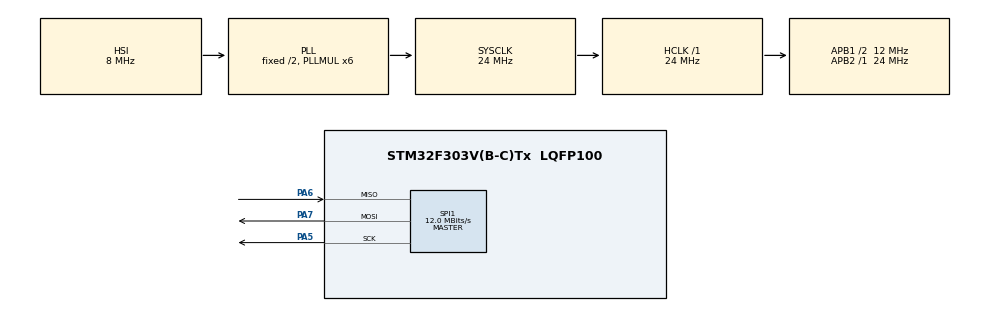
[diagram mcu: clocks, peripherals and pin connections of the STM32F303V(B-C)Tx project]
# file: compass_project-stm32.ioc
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Mcu.Family=STM32F3
Mcu.Name=STM32F303V(B-C)Tx
Mcu.Package=LQFP100
NVIC.PriorityGroup=NVIC_PRIORITYGROUP_0
PA5.Mode=Full_Duplex_Master
PA5.Signal=SPI1_SCK
PA6.Mode=Full_Duplex_Master
PA6.Signal=SPI1_MISO
PA7.Mode=Full_Duplex_Master
PA7.Signal=SPI1_MOSI
ProjectManager.HeapSize=0x200
ProjectManager.StackSize=0x400
ProjectManager.TargetToolchain=STM32CubeIDE
RCC.AHBFreq_Value=24000000
RCC.APB1CLKDivider=RCC_HCLK_DIV2
RCC.APB1Freq_Value=12000000
RCC.APB1TimFreq_Value=24000000
RCC.APB2Freq_Value=24000000
RCC.APB2TimFreq_Value=24000000
RCC.CortexFreq_Value=24000000
RCC.HCLKFreq_Value=24000000
RCC.HSE_VALUE=8000000
RCC.HSI_VALUE=8000000
RCC.LSE_VALUE=32768
RCC.PLLMUL=RCC_PLL_MUL6
RCC.SYSCLKFreq_VALUE=24000000
RCC.SYSCLKSourceVirtual=RCC_SYSCLKSOURCE_PLLCLK
RCC.USBFreq_Value=24000000
SPI1.CalculateBaudRate=12.0 MBits/s
SPI1.DataSize=SPI_DATASIZE_8BIT
SPI1.Direction=SPI_DIRECTION_2LINES
SPI1.Mode=SPI_MODE_MASTER
SPI1.VirtualType=VM_MASTER
board=STM32F3DISCOVERY

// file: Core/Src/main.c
/* USER CODE BEGIN Header */
/**
  ******************************************************************************
  * @file           : main.c
  * @brief          : Main program body
  ******************************************************************************
  * @attention
  *
  * Copyright (c) 2023 STMicroelectronics.
  * All rights reserved.
  *
  * This software is licensed under terms that can be found in the LICENSE file
  * in the root directory of this software component.
  * If no LICENSE file comes with this software, it is provided AS-IS.
  *
  ******************************************************************************
  */
/* USER CODE END Header */
#include "main.h"

SPI_HandleTypeDef hspi1;

void SystemClock_Config(void);
static void MX_GPIO_Init(void);
static void MX_SPI1_Init(void);

/* USER CODE BEGIN 0 */
extern void initialise_monitor_handles(void);
#ifdef DEBUG
#define debug_print printf
#else
#define debug_print(...)
#endif

float ABS(float input){
	float output_val = input;
	if(output_val < 0.0f){
		output_val*=-1.0;
	}
	return output_val;
}
/* USER CODE END 0 */

int main(void)
{
  /* USER CODE BEGIN 1 */
  #ifdef DEBUG
  initialise_monitor_handles();
  #endif
  /* USER CODE END 1 */

  /* MCU Configuration--------------------------------------------------------*/

  /* Reset of all peripherals, Initializes the Flash interface and the Systick. */
  HAL_Init();

  /* USER CODE BEGIN Init */
  BSP_LED_Init(LED4);
  BSP_LED_Init(LED3);
  BSP_LED_Init(LED5);
  BSP_LED_Init(LED7);
  BSP_LED_Init(LED9);
  BSP_LED_Init(LED10);
  BSP_LED_Init(LED8);
  BSP_LED_Init(LED6);
if(BSP_GYRO_Init() != HAL_OK)
  {
    /* Initialization Error */
    Error_Handler();
  }
  /* USER CODE END Init */

  /* Configure the system clock */
  SystemClock_Config();

  /* Initialize all configured peripherals */
  MX_GPIO_Init();
  MX_SPI1_Init();

  /* Infinite loop */
  /* USER CODE BEGIN WHILE */
  while (1)
  {
	/* Gyroscope variable */
	float buffer[3];
	float xval,yval,zval = 0x00;

	/* Read Gyro Angular data */
	BSP_GYRO_GetXYZ(buffer);

	xval = buffer[0];
	yval = buffer[1];
	zval = buffer[2];
	xval = ABS(xval);
	yval = ABS(yval);
	debug_print("xval:%f, yval:%f \n", xval, yval);
	 if(xval>yval)
	  {
	    if(buffer[0] > 5000.0f)
	    {
	      /* LD10 On */
	      BSP_LED_On(LED10);
	      HAL_Delay(10);
	    }
	    else if(buffer[0] < -5000.0f)
	    {
	      /* LED3 On */
	      BSP_LED_On(LED3);
	      HAL_Delay(10);
	    }
	    else
	    {
	      HAL_Delay(10);
	    }
	  }
	  else
	  {
	    if(buffer[1] < -5000.0f)
	    {
	        /* LD6 on */
	        BSP_LED_On(LED6);
	        HAL_Delay(10);
	    }
	    else if(buffer[1] > 5000.0f)
	    {
	        /* LD7 On */
	        BSP_LED_On(LED7);
	        HAL_Delay(10);
	    }
	    else
	    {
	      HAL_Delay(10);
	    }
	  }
	    BSP_LED_Off(LED3);
	    BSP_LED_Off(LED6);
	    BSP_LED_Off(LED7);
	    BSP_LED_Off(LED4);
	    BSP_LED_Off(LED10);
	    BSP_LED_Off(LED8);
	    BSP_LED_Off(LED9);
	    BSP_LED_Off(LED5);
    /* USER CODE END WHILE */

  }
}

void SystemClock_Config(void)
{
  RCC_OscInitTypeDef RCC_OscInitStruct = {0};
  RCC_ClkInitTypeDef RCC_ClkInitStruct = {0};

  /** Initializes the RCC Oscillators according to the specified parameters
  * in the RCC_OscInitTypeDef structure.
  */
  RCC_OscInitStruct.OscillatorType = RCC_OSCILLATORTYPE_HSI;
  RCC_OscInitStruct.HSIState = RCC_HSI_ON;
  RCC_OscInitStruct.HSICalibrationValue = RCC_HSICALIBRATION_DEFAULT;
  RCC_OscInitStruct.PLL.PLLState = RCC_PLL_ON;
  RCC_OscInitStruct.PLL.PLLSource = RCC_PLLSOURCE_HSI;
  RCC_OscInitStruct.PLL.PLLMUL = RCC_PLL_MUL6;
  if (HAL_RCC_OscConfig(&RCC_OscInitStruct) != HAL_OK)
  {
    Error_Handler();
  }

  /** Initializes the CPU, AHB and APB buses clocks
  */
  RCC_ClkInitStruct.ClockType = RCC_CLOCKTYPE_HCLK|RCC_CLOCKTYPE_SYSCLK
                              |RCC_CLOCKTYPE_PCLK1|RCC_CLOCKTYPE_PCLK2;
  RCC_ClkInitStruct.SYSCLKSource = RCC_SYSCLKSOURCE_PLLCLK;
  RCC_ClkInitStruct.AHBCLKDivider = RCC_SYSCLK_DIV1;
  RCC_ClkInitStruct.APB1CLKDivider = RCC_HCLK_DIV2;
  RCC_ClkInitStruct.APB2CLKDivider = RCC_HCLK_DIV1;

  if (HAL_RCC_ClockConfig(&RCC_ClkInitStruct, FLASH_LATENCY_0) != HAL_OK)
  {
    Error_Handler();
  }
}

static void MX_SPI1_Init(void)
{

  /* SPI1 parameter configuration*/
  hspi1.Instance = SPI1;
  hspi1.Init.Mode = SPI_MODE_MASTER;
  hspi1.Init.Direction = SPI_DIRECTION_2LINES;
  hspi1.Init.DataSize = SPI_DATASIZE_8BIT;
  hspi1.Init.CLKPolarity = SPI_POLARITY_LOW;
  hspi1.Init.CLKPhase = SPI_PHASE_1EDGE;
  hspi1.Init.NSS = SPI_NSS_SOFT;
  hspi1.Init.BaudRatePrescaler = SPI_BAUDRATEPRESCALER_2;
  hspi1.Init.FirstBit = SPI_FIRSTBIT_MSB;
  hspi1.Init.TIMode = SPI_TIMODE_DISABLE;
  hspi1.Init.CRCCalculation = SPI_CRCCALCULATION_DISABLE;
  hspi1.Init.CRCPolynomial = 7;
  hspi1.Init.CRCLength = SPI_CRC_LENGTH_DATASIZE;
  hspi1.Init.NSSPMode = SPI_NSS_PULSE_ENABLE;
  if (HAL_SPI_Init(&hspi1) != HAL_OK)
  {
    Error_Handler();
  }

}

static void MX_GPIO_Init(void)
{

  /* GPIO Ports Clock Enable */
  __HAL_RCC_GPIOA_CLK_ENABLE();

}

void Error_Handler(void)
{
  __disable_irq();
  while (1)
  {
  }
}
